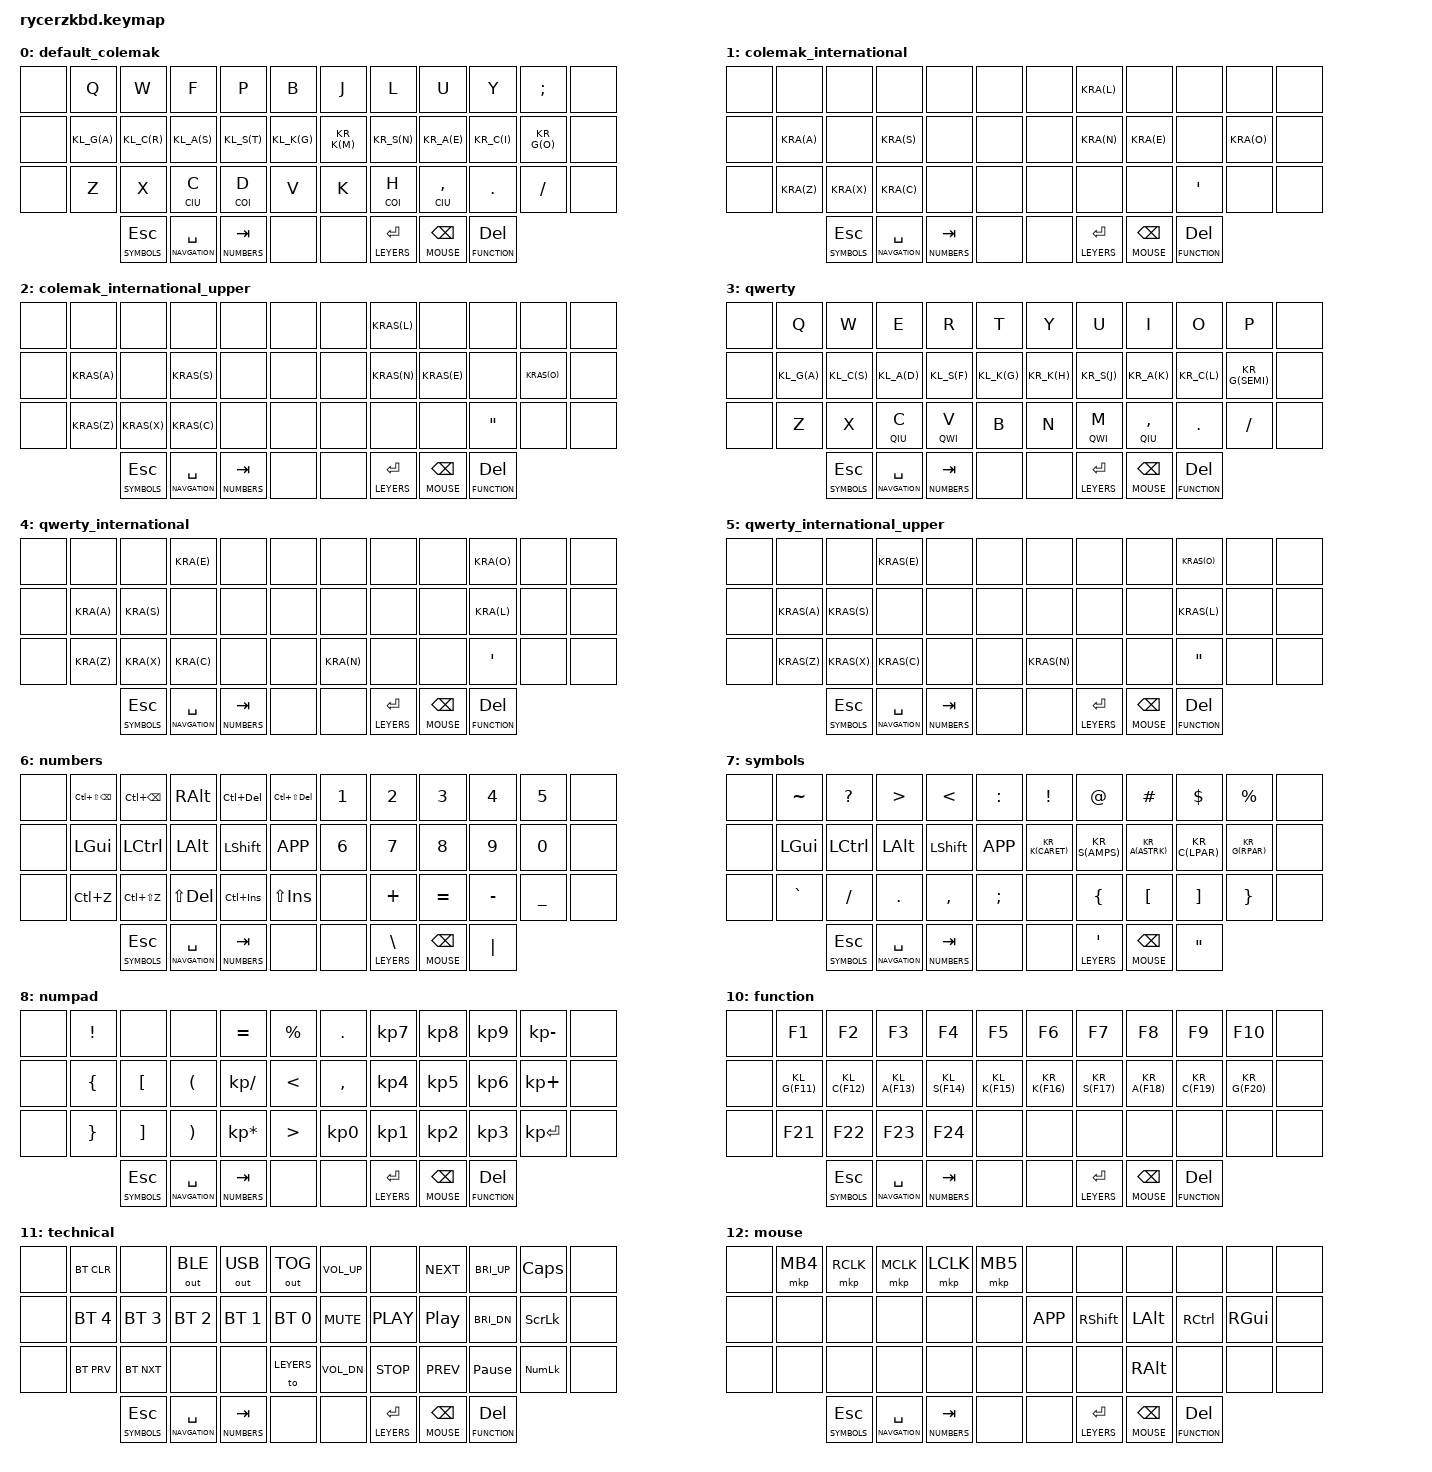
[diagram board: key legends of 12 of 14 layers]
/*
 * Copyright (c) 2020 The ZMK Contributors
 *
 * SPDX-License-Identifier: MIT
 */

#include <behaviors.dtsi>
#include <dt-bindings/zmk/keys.h>
#include <dt-bindings/zmk/bt.h>
#include <dt-bindings/zmk/outputs.h>
#include <dt-bindings/zmk/mouse.h>

#define COL 0
#define COI 1
#define CIU 2
#define QWE 3
#define QWI 4
#define QIU 5
#define NUMBERS 6
#define SYMBOLS 7
#define NUMPAD 8
#define NAVGATION 9
#define FUNCTION 10
#define TECHMEDIA 11
#define MOUSE 12
#define LEYERS 13


#define KRA(keycode) &kp RA(keycode)
#define KRAS(keycode) &kp RA(LS(keycode)) 
//left
#define KL_K(keycode) &hrl K_APP keycode
#define KL_S(keycode) &hrl LSHFT keycode
#define KL_C(keycode) &hrl LCTRL keycode
#define KL_A(keycode) &hrl LALT keycode
#define KL_G(keycode) &hrl LGUI keycode
//right
#define KR_G(keycode) &hrr RGUI keycode
#define KR_A(keycode) &hrr LALT keycode
#define KR_C(keycode) &hrr RCTRL keycode
#define KR_S(keycode) &hrr RSHFT keycode
#define KR_K(keycode) &hrr K_APP keycode
//thumbs
#define KL_ESC &tmh SYMBOLS ESCAPE 
#define KL_SPC &tmh NAVGATION SPACE
#define KL_TAB &tmh NUMBERS TAB  
#define KL_ENT &tmh LEYERS ENTER
#define KL_BSPC &tmh MOUSE BSPC
#define KL_DEL &tmh FUNCTION DEL
#define KL_BSLH &tmh LEYERS BSLH
#define KL_APOS &tmh LEYERS APOS


#define PT_CAM &kp LG(LS(O)) 
#define PT_MIC &kp LG(LS(A))
#define PT_ALL &kp LG(LS(Q))
 


/ {
    behaviors {
        hrl: left_hand_home_row_hold_tap {
            compatible = "zmk,behavior-hold-tap";
            label = "LEFT_POSITIONAL_HOME_ROW_HOLD_TAP";
            #binding-cells = <2>;
            flavor = "tap-preferred";
            tapping-term-ms = <240>;
            quick-tap-ms = <0>;   
            bindings = <&kp>, <&kp>;
            hold-trigger-key-positions = <6 7 8 9 10 13 14 15 16 17 18 19 20 21 22 30 31 32 33 34 41 42 43>;
        };
        orl: left_hand_other_row_hold_tap {
            compatible = "zmk,behavior-hold-tap";
            label = "LEFT_POSITIONAL_HOLD_TAP";
            #binding-cells = <2>;
            flavor = "tap-preferred";
            tapping-term-ms = <240>;
            quick-tap-ms = <0>;
            bindings = <&kp>, <&kp>;
            hold-trigger-key-positions = <6 7 8 9 10 18 19 20 21 22 30 31 32 33 34 41 42 43>;
        };
        ihl: lef_international_momentary_leyer_hold_tap {
            compatible = "zmk,behavior-hold-tap";
            label = "LEFT_MOMENTARY_LEYER_HOLD_TAP";
            #binding-cells = <2>;
            flavor = "tap-preferred";
            tapping-term-ms = <240>;
            quick-tap-ms = <0>;
            hold-trigger-key-positions = <6 7 8 9 10 18 19 20 21 22 30 31 32 33 34 41 42 43>;
            bindings = <&mo>, <&kp>;
        };  
        hrr: right_hand_home_row_hold_tap {
            compatible = "zmk,behavior-hold-tap";
            label = "RIGHT_POSITIONAL_HOME_ROW_HOLD_TAP";
            #binding-cells = <2>;
            flavor = "tap-preferred";
            tapping-term-ms = <240>;
            quick-tap-ms = <0>;
            bindings = <&kp>, <&kp>;
            hold-trigger-key-positions = <1 2 3 4 5 13 14 15 16 17 18 19 20 21 22 25 26 27 28 29 36 37 38>;
        };
        orr: right_hand_other_row_hold_tap {
            compatible = "zmk,behavior-hold-tap";
            label = "RIGHT_POSITIONAL_HOLD_TAP";
            #binding-cells = <2>;
            flavor = "tap-preferred";
            tapping-term-ms = <240>;
            quick-tap-ms = <0>;
            bindings = <&kp>, <&kp>;
            hold-trigger-key-positions = <1 2 3 4 5 13 14 15 16 17 25 26 27 28 29 36 37 38>;
        };
        ihr: right_international_momentary_leyer_hold_tap {
            compatible = "zmk,behavior-hold-tap";
            label = "RIGHT_MOMENTARY_LEYER_HOLD_TAP";
            #binding-cells = <2>;
            flavor = "tap-preferred";
            tapping-term-ms = <240>;
            quick-tap-ms = <0>;
            hold-trigger-key-positions = <1 2 3 4 5 13 14 15 16 17 25 26 27 28 29 36 37 38>;
            bindings = <&mo>, <&kp>;
           };
        tmh: thumb_row_hold_tap {
            compatible = "zmk,behavior-hold-tap";
            label = "THUMB_MOMENTARY_HOLD_TAP";
            #binding-cells = <2>;
            flavor = "tap-preferred";
            tapping-term-ms = <240>;
            quick-tap-ms = <0>;
            bindings = <&mo>, <&kp>;
        };

    };

        keymap {
                compatible = "zmk,keymap";
                default_colemak {
                        bindings = <
//----|--------------|-------------------|--------------|----------------|----------------||----------------|---------------|----------------|------------------|----------------|-------
&none    &kp Q         &kp W               &kp F          &kp P            &kp B             &kp J            &kp L           &kp U            &kp Y              &kp SEMI         &none
&none    KL_G(A)       KL_C(R)             KL_A(S)        KL_S(T)          KL_K(G)           KR_K(M)          KR_S(N)         KR_A(E)          KR_C(I)            KR_G(O)          &none
&none    &kp Z         &kp X               &ihl CIU C     &ihl COI D       &kp V             &kp K            &ihr COI H      &ihr CIU COMMA   &kp PERIOD         &kp SLASH        &none
                       KL_ESC              KL_SPC         KL_TAB           &none             &none            KL_ENT          KL_BSPC          KL_DEL           
                        >;
                };
                colemak_international {
                        bindings = <
//----|--------------|-------------------|--------------|----------------|----------------||----------------|---------------|----------------|------------------|----------------|-------
&none    &none         &none               &none          &none            &none             &none            KRA(L)          &none            &none              &none            &none
&none    KRA(A)        &none               KRA(S)         &none            &none             &none            KRA(N)          KRA(E)           &none              KRA(O)           &none
&none    KRA(Z)        KRA(X)              KRA(C)         &none            &none             &none            &none           &none            &kp APOS           &none            &none
                       KL_ESC              KL_SPC         KL_TAB           &none             &none            KL_ENT          KL_BSPC          KL_DEL
                        >;
                };
                colemak_international_upper {
                        bindings = <
//----|--------------|-------------------|--------------|----------------|----------------||----------------|---------------|----------------|------------------|----------------|-------
&none    &none         &none               &none          &none            &none             &none            KRAS(L)         &none            &none              &none            &none
&none    KRAS(A)       &none               KRAS(S)        &none            &none             &none            KRAS(N)         KRAS(E)          &none              KRAS(O)          &none
&none    KRAS(Z)       KRAS(X)             KRAS(C)        &none            &none             &none            &none           &none            &kp DQT            &none            &none
                       KL_ESC              KL_SPC         KL_TAB           &none             &none            KL_ENT          KL_BSPC          KL_DEL
                        >;
                };
                qwerty {
                        bindings = <
//----|--------------|-------------------|--------------|----------------|----------------||----------------|---------------|----------------|------------------|----------------|-------						
&none    &kp Q         &kp W               &kp E          &kp R            &kp T             &kp Y            &kp U           &kp I            &kp O              &kp P            &none
&none    KL_G(A)       KL_C(S)             KL_A(D)        KL_S(F)          KL_K(G)           KR_K(H)          KR_S(J)         KR_A(K)          KR_C(L)            KR_G(SEMI)       &none
&none    &kp Z         &kp X               &ihl QIU C     &ihl QWI V       &kp B             &kp N            &ihr QWI M      &ihr QIU COMMA   &kp PERIOD         &kp SLASH        &none
                       KL_ESC              KL_SPC         KL_TAB           &none             &none            KL_ENT          KL_BSPC          KL_DEL
                        >;
                };
                qwerty_international {
                        bindings = <
//----|--------------|-------------------|--------------|----------------|----------------||----------------|---------------|----------------|------------------|----------------|-------
&none    &none         &none               KRA(E)         &none            &none             &none            &none           &none            KRA(O)             &none            &none
&none    KRA(A)        KRA(S)              &none          &none            &none             &none            &none           &none            KRA(L)             &none            &none
&none    KRA(Z)        KRA(X)              KRA(C)         &none            &none             KRA(N)           &none           &none            &kp APOS           &none            &none
                       KL_ESC              KL_SPC         KL_TAB           &none             &none            KL_ENT          KL_BSPC          KL_DEL
                        >;
                };
                qwerty_international_upper {
                        bindings = <
//----|--------------|-------------------|--------------|----------------|----------------||----------------|---------------|----------------|------------------|----------------|-------
&none    &none         &none               KRAS(E)        &none            &none             &none            &none           &none            KRAS(O)            &none            &none
&none    KRAS(A)       KRAS(S)             &none          &none            &none             &none            &none           &none            KRAS(L)            &none            &none
&none    KRAS(Z)       KRAS(X)             KRAS(C)        &none            &none             KRAS(N)          &none           &none            &kp DQT            &none            &none
                       KL_ESC              KL_SPC         KL_TAB           &none             &none            KL_ENT          KL_BSPC          KL_DEL
                        >;
                };
                numbers {
                        bindings = <
//----|------------------|-------------------|--------------|----------------|----------------||----------------|---------------|----------------|------------------|----------------|-------
&none    &kp LC(LS(BSPC))  &kp LC(BSPC)        &kp RALT       &kp LC(DEL)      &kp LC(LS(DEL))   &kp N1           &kp N2          &kp N3           &kp N4             &kp N5           &none
&none    &kp LGUI          &kp LCTRL           &kp LALT       &kp LSHFT        &kp K_APP         &kp N6           &kp N7          &kp N8           &kp N9             &kp N0           &none
&none    &kp LC(Z)         &kp LC(LS(Z))       &kp LS(DEL)    &kp LC(INS)      &kp LS(INS)       &none            &kp PLUS        &kp EQUAL        &kp MINUS          &kp UNDER        &none
                           KL_ESC              KL_SPC         KL_TAB           &none             &none            KL_BSLH         KL_BSPC          &kp PIPE
                        >;
                };
				symbols {
                        bindings = <
//----|--------------|-------------------|--------------|----------------|----------------||----------------|---------------|----------------|------------------|----------------|-------
&none    &kp TILDE     &kp QMARK           &kp GT         &kp LT           &kp COLON         &kp EXCL         &kp AT          &kp HASH         &kp DOLLAR         &kp PRCNT        &none
&none    &kp LGUI      &kp LCTRL           &kp LALT       &kp LSHFT        &kp K_APP         KR_K(CARET)      KR_S(AMPS)      KR_A(ASTRK)      KR_C(LPAR)         KR_G(RPAR)       &none
&none    &kp GRAVE     &kp SLASH           &kp PERIOD     &kp COMMA        &kp SEMI          &none            &kp LBRC        &kp LBKT         &kp RBKT           &kp RBRC         &none
                       KL_ESC              KL_SPC         KL_TAB           &none             &none            KL_APOS         KL_BSPC         &kp DQT
                        >;
                };
                numpad {
                        bindings = <
//----|--------------|-------------------|--------------|----------------|----------------||----------------|---------------|----------------|------------------|----------------|-------
&none    &kp EXCL      &none               &none          &kp EQUAL        &kp PRCNT         &kp DOT          &kp KP_N7       &kp KP_N8        &kp KP_N9          &kp KP_MINUS     &none
&none    &kp LBRC      &kp LBKT            &kp LPAR       &kp KP_SLASH     &kp LT            &kp COMMA        &kp KP_N4       &kp KP_N5        &kp KP_N6          &kp KP_PLUS      &none
&none    &kp RBRC      &kp RBKT            &kp RPAR       &kp KP_MULTIPLY  &kp GT            &kp KP_N0        &kp KP_N1       &kp KP_N2        &kp KP_N3          &kp KP_ENTER     &none
                       KL_ESC              KL_SPC         KL_TAB           &none             &none            KL_ENT          KL_BSPC          KL_DEL
                        >;
                };
                navigation {
                        bindings = <
//----|---------------|-------------------|------------------|------------------|------------||-------------|---------------|----------------|------------------|----------------|-------
&none    &kp LC(TAB)    &none               &kp LC(LEFT)       &kp LC(RIGHT)      &none         &kp INS       &kp HOME        &kp UP           &kp END            &kp LA(RIGHT)    &none
&none    KL_G(LA(TAB))  KL_C(LC(LS(TAB)))   KL_A(LA(LS(TAB)))  KL_S(LA(LC(TAB)))  &kp K_APP     &kp DEL       &kp LEFT        &kp DOWN         &kp RIGHT          &kp LA(LEFT)     &none
&none    &none          &none               &kp LC(LG(LEFT))   &kp LC(LG(RIGHT))  &none         &kp RGUI      &kp PG_DN       &kp PSCRN        &kp PG_UP          &kp K_APP        &none
                        KL_ESC              KL_SPC             KL_TAB             &none         &none         KL_ENT          &kp LC(BSPC)     &kp LC(DEL)
                        >;
                };
                function {
                        bindings = <
//----|--------------|-------------------|--------------|----------------|----------------||----------------|---------------|----------------|------------------|----------------|-------
&none    &kp F1        &kp F2              &kp F3         &kp F4           &kp F5            &kp F6           &kp F7          &kp F8           &kp F9             &kp F10          &none
&none    KL_G(F11)     KL_C(F12)           KL_A(F13)      KL_S(F14)        KL_K(F15)         KR_K(F16)        KR_S(F17)       KR_A(F18)        KR_C(F19)          KR_G(F20)        &none
&none    &kp F21       &kp F22             &kp F23        &kp F24          &none             &none            &none           &none            &none              &none            &none
                       KL_ESC              KL_SPC         KL_TAB           &none             &none            KL_ENT          KL_BSPC          KL_DEL
                        >;
                };
                technical {
                        bindings = <
//----|--------------|-------------------|--------------|----------------|----------------||----------------|---------------|----------------|------------------|----------------|-------
&none    &bt BT_CLR    &none               &out OUT_BLE   &out OUT_USB     &out OUT_TOG      &kp C_VOL_UP     &none           &kp C_NEXT       &kp C_BRI_UP       &kp CAPS         &none
&none    &bt BT_SEL 4  &bt BT_SEL 3        &bt BT_SEL 2   &bt BT_SEL 1     &bt BT_SEL 0      &kp C_MUTE       &kp C_PLAY      &kp C_PP         &kp C_BRI_DN       &kp SLCK         &none
&none    &bt BT_PRV    &bt BT_NXT          &none          &none            &to LEYERS        &kp C_VOL_DN     &kp C_STOP      &kp C_PREV       &kp PAUSE_BREAK    &kp KP_NUM       &none
                       KL_ESC              KL_SPC         KL_TAB           &none             &none            KL_ENT          KL_BSPC          KL_DEL
                        >;
                };
                mouse {
                        bindings = <
//----|--------------|-------------------|--------------|----------------|----------------||----------------|---------------|----------------|------------------|----------------|-------
&none    &mkp MB4      &mkp RCLK           &mkp MCLK      &mkp LCLK        &mkp MB5          &none            &none           &none            &none              &none            &none
&none    &none         &none               &none          &none            &none             &kp K_APP        &kp RSHFT       &kp LALT         &kp RCTRL          &kp RGUI         &none
&none    &none         &none               &none          &none            &none             &none            &none           &kp RALT         &none              &none            &none
                       KL_ESC              KL_SPC         KL_TAB           &none             &none            KL_ENT          KL_BSPC          KL_DEL
                        >;
                };
                leyers {
                        bindings = <
//----|--------------|-------------------|--------------|----------------|----------------||----------------|---------------|----------------|------------------|----------------|-------
&none    &to NUMBERS   &to MOUSE           &none          &to NUMPAD       PT_CAM            &none            &none           &none            &none              &none            &none
&none    &to SYMBOLS   &to QWE             &to COL        &to COL          PT_MIC            &bt BT_SEL 0     &bt BT_SEL 1    &bt BT_SEL 2     &bt BT_SEL 3       &bt BT_SEL 4     &none
&none    &to FUNCTION  &none               &to NAVGATION  &to TECHMEDIA    PT_ALL            &none            &none           &none            &none              &none            &none
                       KL_ESC              KL_SPC         KL_TAB           &none             &none            KL_ENT          KL_BSPC          KL_DEL
                        >;
                };
        };
};
